VERSION "ADAS Integration Lab Phase 3"

NS_ :

BS_:

BU_: VehicleECU RadarECU ADAS

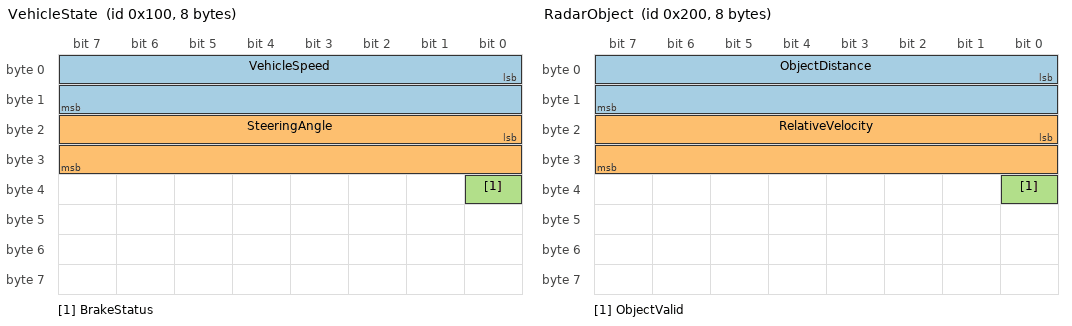
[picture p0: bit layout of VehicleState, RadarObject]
BO_ 256 VehicleState: 8 VehicleECU
 SG_ VehicleSpeed : 0|16@1+ (0.1,0) [0|300] "km/h" ADAS
 SG_ SteeringAngle : 16|16@1- (0.1,0) [-720|720] "deg" ADAS
 SG_ BrakeStatus : 32|1@1+ (1,0) [0|1] "" ADAS

BO_ 512 RadarObject: 8 RadarECU
 SG_ ObjectDistance : 0|16@1+ (0.1,0) [0|500] "m" ADAS
 SG_ RelativeVelocity : 16|16@1- (0.01,0) [-100|100] "m/s" ADAS
 SG_ ObjectValid : 32|1@1+ (1,0) [0|1] "" ADAS

CM_ BO_ 256 "Vehicle state; reserved bits are zero when transmitted and ignored by the decoder.";
CM_ BO_ 512 "Closest radar object; reserved bits are zero when transmitted and ignored by the decoder.";
CM_ SG_ 512 RelativeVelocity "Positive means approaching the obstacle; negative means moving away.";
VAL_ 256 BrakeStatus 0 "Released" 1 "Pressed";
VAL_ 512 ObjectValid 0 "Invalid" 1 "Valid";
